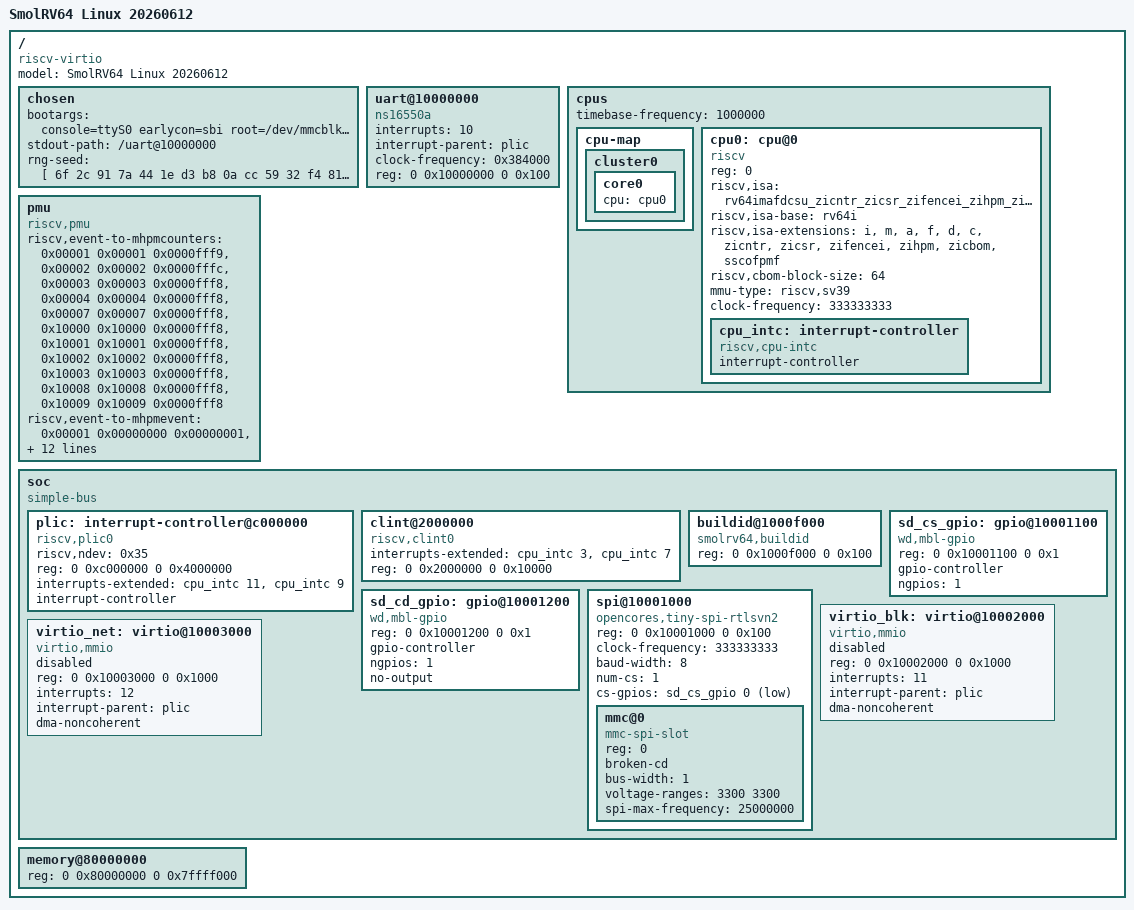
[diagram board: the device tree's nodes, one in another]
/dts-v1/;

/ {
        #address-cells = <2>;
        #size-cells = <2>;
        compatible = "riscv-virtio";
        model = "SmolRV64 Linux 20260612";

        chosen {
		bootargs = "console=ttyS0 earlycon=sbi root=/dev/mmcblk0p1 rw ignore_loglevel random.trust_bootloader=on";
		stdout-path = "/uart@10000000";

                /* Development-only static seed: replace with per-boot random bytes later. */
                rng-seed = [
                        6f 2c 91 7a 44 1e d3 b8
                        0a cc 59 32 f4 81 25 9d
                        e7 10 ba 6c 38 5f 02 c1
                        93 d4 76 af 20 8b ee 41
                        15 62 9a cd 57 03 b4 f8
                        80 2d 11 6e a9 4c 73 05
                        dc 37 f1 98 24 bb 60 0f
                        4a e2 7d 36 c5 19 8c a0
                ];
	};

	uart@10000000 {
		interrupts = <10>;
		interrupt-parent = <&plic>;
		clock-frequency = <0x384000>;
		reg = <0 0x10000000 0 0x100>;
		compatible = "ns16550a";
	};

	cpus {
		#address-cells = <1>;
		#size-cells = <0>;
		timebase-frequency = <1000000>; /* 1 MHz, a 10X lie */

		cpu-map {

			cluster0 {

				core0 {
					cpu = <&cpu0>;
				};
			};
		};

		cpu0: cpu@0 {
			device_type = "cpu";
			reg = <0>;
			status = "okay";
			compatible = "riscv";
			riscv,isa = "rv64imafdcsu_zicntr_zicsr_zifencei_zihpm_zicbom_sscofpmf";
			riscv,isa-base = "rv64i";
			riscv,isa-extensions = "i", "m", "a", "f", "d", "c",
				"zicntr", "zicsr", "zifencei", "zihpm",
				"zicbom", "sscofpmf";
			riscv,cbom-block-size = <64>;
			mmu-type = "riscv,sv39";
			clock-frequency = <333333333>;

			cpu_intc: interrupt-controller {
				#interrupt-cells = <1>;
				interrupt-controller;
				compatible = "riscv,cpu-intc";
			};
		};
	};

	pmu {
		compatible = "riscv,pmu";
		riscv,event-to-mhpmcounters =
			<0x00001 0x00001 0x0000fff9>,
			<0x00002 0x00002 0x0000fffc>,
			<0x00003 0x00003 0x0000fff8>,
			<0x00004 0x00004 0x0000fff8>,
			<0x00007 0x00007 0x0000fff8>,
			<0x10000 0x10000 0x0000fff8>,
			<0x10001 0x10001 0x0000fff8>,
			<0x10002 0x10002 0x0000fff8>,
			<0x10003 0x10003 0x0000fff8>,
			<0x10008 0x10008 0x0000fff8>,
			<0x10009 0x10009 0x0000fff8>;
		riscv,event-to-mhpmevent =
			<0x00001 0x00000000 0x00000001>,
			<0x00002 0x00000000 0x00000002>,
			<0x00003 0x00000000 0x00000100>,
			<0x00004 0x00000000 0x00000102>,
			<0x00007 0x00000000 0x00000202>,
			<0x10000 0x00000000 0x00000110>,
			<0x10001 0x00000000 0x00000113>,
			<0x10002 0x00000000 0x00000111>,
			<0x10003 0x00000000 0x00000113>,
			<0x10008 0x00000000 0x00000100>,
			<0x10009 0x00000000 0x00000102>;
		riscv,raw-event-to-mhpmcounters =
			<0x00000000 0x00000000 0xffffffff 0xffff0000 0x0000fff8>;
	};

	soc {
		#address-cells = <2>;
		#size-cells = <2>;
		compatible = "simple-bus";
		ranges;

		plic: interrupt-controller@c000000 {
			riscv,ndev = <0x35>;
			reg = <0 0xc000000 0 0x4000000>;
			interrupts-extended = <&cpu_intc 11 &cpu_intc 9>;
			interrupt-controller;
			compatible = "riscv,plic0";
			#interrupt-cells = <1>;
			#address-cells = <0>;
		};

		clint@2000000 {
			interrupts-extended = <&cpu_intc 3 &cpu_intc 7>;
			reg = <0 0x2000000 0 0x10000>;
			compatible = "riscv,clint0";
		};

		buildid@1000f000 {
			compatible = "smolrv64,buildid";
			reg = <0 0x1000f000 0 0x100>;
		};

		sd_cs_gpio: gpio@10001100 {
			compatible = "wd,mbl-gpio";
			reg = <0 0x10001100 0 0x1>;
			reg-names = "dat";
			gpio-controller;
			#gpio-cells = <2>;
			ngpios = <1>;
		};

		sd_cd_gpio: gpio@10001200 {
			compatible = "wd,mbl-gpio";
			reg = <0 0x10001200 0 0x1>;
			reg-names = "dat";
			gpio-controller;
			#gpio-cells = <2>;
			ngpios = <1>;
			no-output;
		};

		spi@10001000 {
			compatible = "opencores,tiny-spi-rtlsvn2";
			reg = <0 0x10001000 0 0x100>;
			clock-frequency = <333333333>;
			baud-width = <8>;
			num-cs = <1>;
			cs-gpios = <&sd_cs_gpio 0 1>; /* GPIO_ACTIVE_LOW */
			#address-cells = <1>;
			#size-cells = <0>;

			mmc@0 {
				compatible = "mmc-spi-slot";
				reg = <0>;
				broken-cd;
				bus-width = <1>;
				voltage-ranges = <3300 3300>;
				spi-max-frequency = <25000000>;
			};
		};

		virtio_blk: virtio@10002000 {
			compatible = "virtio,mmio";
			reg = <0 0x10002000 0 0x1000>;
			interrupts = <11>;
			interrupt-parent = <&plic>;
			dma-noncoherent;
			status = "disabled";
		};

		virtio_net: virtio@10003000 {
			compatible = "virtio,mmio";
			reg = <0 0x10003000 0 0x1000>;
			interrupts = <12>;
			interrupt-parent = <&plic>;
			dma-noncoherent;
			status = "disabled";
		};
	};

	memory@80000000 {
		device_type = "memory";
		reg = <0 0x80000000 0 0x7ffff000>; // 2 GiB MiB
	};
};
